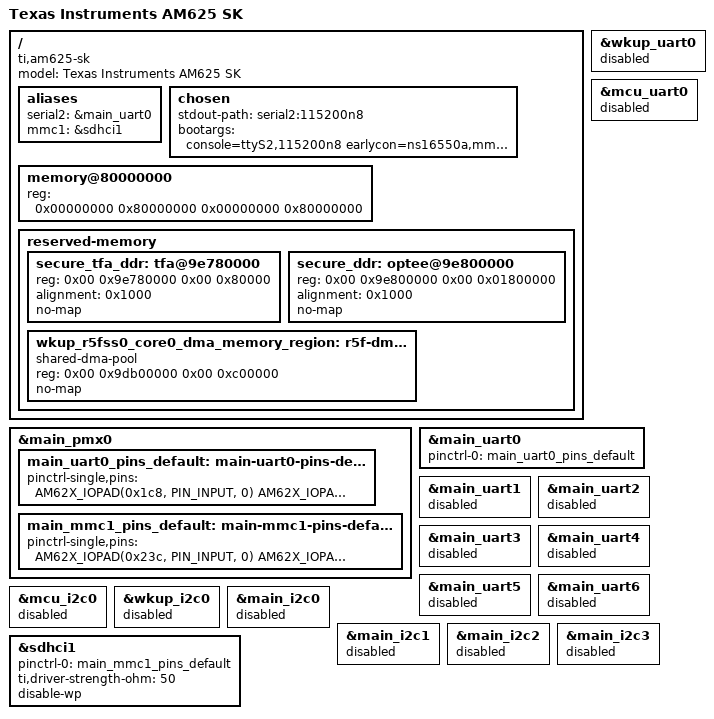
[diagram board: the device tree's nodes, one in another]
// SPDX-License-Identifier: GPL-2.0
/*
 * AM625 SK: https://www.ti.com/lit/zip/sprr448
 *
 * Copyright (C) 2021-2022 Texas Instruments Incorporated - https://www.ti.com/
 */

/dts-v1/;

#include <dt-bindings/leds/common.h>
#include <dt-bindings/gpio/gpio.h>
#include <dt-bindings/net/ti-dp83867.h>
#include "k3-am625.dtsi"

/ {
	compatible =  "ti,am625-sk", "ti,am625";
	model = "Texas Instruments AM625 SK";

	aliases {
		serial2 = &main_uart0;
		mmc1 = &sdhci1;
	};

	chosen {
		stdout-path = "serial2:115200n8";
		bootargs = "console=ttyS2,115200n8 earlycon=ns16550a,mmio32,0x02800000";
	};

	memory@80000000 {
		device_type = "memory";
		/* 2G RAM */
		reg = <0x00000000 0x80000000 0x00000000 0x80000000>;

	};

	reserved-memory {
		#address-cells = <2>;
		#size-cells = <2>;
		ranges;

		secure_tfa_ddr: tfa@9e780000 {
			reg = <0x00 0x9e780000 0x00 0x80000>;
			alignment = <0x1000>;
			no-map;
		};

		secure_ddr: optee@9e800000 {
			reg = <0x00 0x9e800000 0x00 0x01800000>; /* for OP-TEE */
			alignment = <0x1000>;
			no-map;
		};

		wkup_r5fss0_core0_dma_memory_region: r5f-dma-memory@9db00000 {
			compatible = "shared-dma-pool";
			reg = <0x00 0x9db00000 0x00 0xc00000>;
			no-map;
		};
	};
};

&main_pmx0 {
	main_uart0_pins_default: main-uart0-pins-default {
		pinctrl-single,pins = <
			AM62X_IOPAD(0x1c8, PIN_INPUT, 0) /* (D14) UART0_RXD */
			AM62X_IOPAD(0x1cc, PIN_OUTPUT, 0) /* (E14) UART0_TXD */
		>;
	};

	main_mmc1_pins_default: main-mmc1-pins-default {
		pinctrl-single,pins = <
			AM62X_IOPAD(0x23c, PIN_INPUT, 0) /* (A21) MMC1_CMD */
			AM62X_IOPAD(0x234, PIN_INPUT, 0) /* (B22) MMC1_CLK */
			AM62X_IOPAD(0x230, PIN_INPUT, 0) /* (A22) MMC1_DAT0 */
			AM62X_IOPAD(0x22c, PIN_INPUT, 0) /* (B21) MMC1_DAT1 */
			AM62X_IOPAD(0x228, PIN_INPUT, 0) /* (C21) MMC1_DAT2 */
			AM62X_IOPAD(0x224, PIN_INPUT, 0) /* (D22) MMC1_DAT3 */
			AM62X_IOPAD(0x240, PIN_INPUT, 0) /* (D17) MMC1_SDCD */
		>;
	};
};

&wkup_uart0 {
	/* WKUP UART0 is used by DM firmware */
	status = "reserved";
};

&mcu_uart0 {
	status = "disabled";
};

&main_uart0 {
	pinctrl-names = "default";
	pinctrl-0 = <&main_uart0_pins_default>;
};

&main_uart1 {
	/* Main UART1 is used by TIFS firmware */
	status = "reserved";
};

&main_uart2 {
	status = "disabled";
};

&main_uart3 {
	status = "disabled";
};

&main_uart4 {
	status = "disabled";
};

&main_uart5 {
	status = "disabled";
};

&main_uart6 {
	status = "disabled";
};

&mcu_i2c0 {
	status = "disabled";
};

&wkup_i2c0 {
	status = "disabled";
};

&main_i2c0 {
	status = "disabled";
};

&main_i2c1 {
	status = "disabled";
};

&main_i2c2 {
	status = "disabled";
};

&main_i2c3 {
	status = "disabled";
};

&sdhci1 {
	pinctrl-names = "default";
	pinctrl-0 = <&main_mmc1_pins_default>;
	ti,driver-strength-ohm = <50>;
	disable-wp;
};
